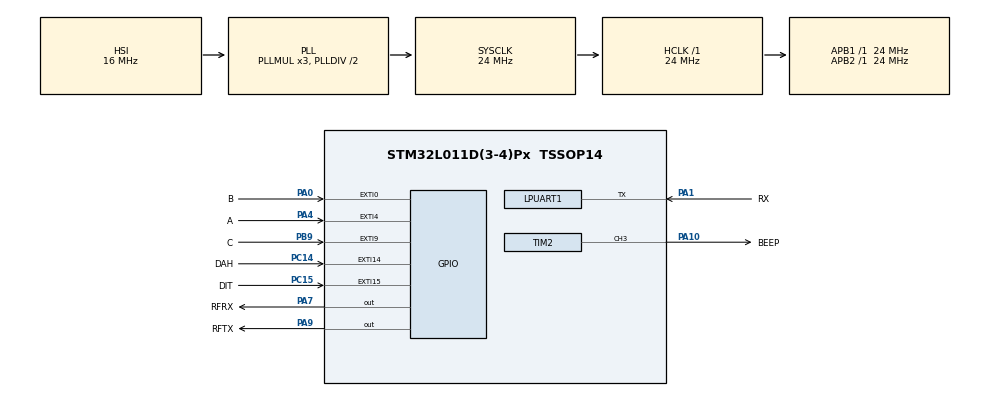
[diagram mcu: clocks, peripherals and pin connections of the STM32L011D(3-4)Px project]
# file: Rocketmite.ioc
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Dma.LPUART1_RX.0.Direction=DMA_PERIPH_TO_MEMORY
Dma.LPUART1_RX.0.Instance=DMA1_Channel3
Dma.LPUART1_RX.0.MemDataAlignment=DMA_MDATAALIGN_BYTE
Dma.LPUART1_RX.0.MemInc=DMA_MINC_ENABLE
Dma.LPUART1_RX.0.Mode=DMA_NORMAL
Dma.LPUART1_RX.0.PeriphDataAlignment=DMA_PDATAALIGN_BYTE
Dma.LPUART1_RX.0.PeriphInc=DMA_PINC_DISABLE
Dma.LPUART1_RX.0.Priority=DMA_PRIORITY_LOW
Dma.Request0=LPUART1_RX
LPUART1.BaudRate=115200
LPUART1.Mode=UART_MODE_RX
Mcu.Family=STM32L0
Mcu.Name=STM32L011D(3-4)Px
Mcu.Package=TSSOP14
NVIC.DMA1_Channel2_3_IRQn=true\:0\:0\:false\:false\:true\:false\:true\:true
NVIC.LPUART1_IRQn=true\:0\:0\:false\:false\:true\:true\:true\:true
NVIC.TIM21_IRQn=true\:2\:0\:true\:false\:true\:true\:true\:true
PA0-CK_IN.GPIO_Label=B
PA0-CK_IN.GPIO_ModeDefaultEXTI=GPIO_MODE_EVT_FALLING
PA0-CK_IN.Signal=GPXTI0
PA1.GPIO_Label=RX
PA1.Mode=Half_duplex(single_wire_mode)
PA1.Signal=LPUART1_TX
PA10.GPIO_Label=BEEP
PA10.Signal=S_TIM2_CH3
PA13.Mode=Serial_Wire
PA13.Signal=SYS_SWDIO
PA14.Mode=Serial_Wire
PA14.Signal=SYS_SWCLK
PA4.GPIO_Label=A
PA4.GPIO_ModeDefaultEXTI=GPIO_MODE_IT_FALLING
PA4.Signal=GPXTI4
PA7.GPIO_Label=RFRX
PA7.Signal=GPIO_Output
PA9.GPIO_Label=RFTX
PA9.Signal=GPIO_Output
PB9-BOOT0.GPIO_Label=C
PB9-BOOT0.Signal=GPXTI9
PC14-OSC32_IN.GPIO_Label=DAH
PC14-OSC32_IN.GPIO_ModeDefaultEXTI=GPIO_MODE_IT_FALLING
PC14-OSC32_IN.GPIO_PuPd=GPIO_PULLUP
PC14-OSC32_IN.Signal=GPXTI14
PC15-OSC32_OUT.GPIO_Label=DIT
PC15-OSC32_OUT.GPIO_ModeDefaultEXTI=GPIO_MODE_IT_FALLING
PC15-OSC32_OUT.GPIO_PuPd=GPIO_PULLUP
PC15-OSC32_OUT.Signal=GPXTI15
ProjectManager.HeapSize=0x200
ProjectManager.StackSize=0x400
ProjectManager.TargetToolchain=MDK-ARM V5.32
RCC.AHBFreq_Value=24000000
RCC.APB1Freq_Value=24000000
RCC.APB1TimFreq_Value=24000000
RCC.APB2Freq_Value=24000000
RCC.APB2TimFreq_Value=24000000
RCC.HCLKFreq_Value=24000000
RCC.HSE_VALUE=8000000
RCC.HSI16_VALUE=16000000
RCC.HSI_VALUE=16000000
RCC.LSE_VALUE=32768
RCC.MSI_VALUE=2097000
RCC.SYSCLKFreq_VALUE=24000000
RCC.SYSCLKSource=RCC_SYSCLKSOURCE_PLLCLK
RCC.VCOOutputFreq_Value=48000000
SH.S_TIM2_CH3.0=TIM2_CH3,PWM Generation3 CH3
TIM2.AutoReloadPreload=TIM_AUTORELOAD_PRELOAD_ENABLE
TIM2.Channel-PWM\ Generation3\ CH3=TIM_CHANNEL_3
TIM2.OCMode_PWM-PWM\ Generation3\ CH3=TIM_OCMODE_PWM2
TIM2.OCPolarity_3=TIM_OCPOLARITY_LOW
TIM2.Period=1000-1
TIM2.Prescaler=24-1
TIM2.Pulse-PWM\ Generation3\ CH3=1000
TIM21.AutoReloadPreload=TIM_AUTORELOAD_PRELOAD_ENABLE
TIM21.Period=2000-1
TIM21.Prescaler=23-1
VP_TIM21_VS_ClockSourceINT.Mode=Internal
VP_TIM2_VS_ClockSourceINT.Mode=Internal
board=custom

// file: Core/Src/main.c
/* USER CODE BEGIN Header */
/**
  ******************************************************************************
  * @file           : main.c
  * @brief          : Main program body
  ******************************************************************************
  * @attention
  *
  * Copyright (c) 2024 STMicroelectronics.
  * All rights reserved.
  *
  * This software is licensed under terms that can be found in the LICENSE file
  * in the root directory of this software component.
  * If no LICENSE file comes with this software, it is provided AS-IS.
  *
  ******************************************************************************
  */
/* USER CODE END Header */
#include "main.h"
#include "dma.h"
#include "usart.h"
#include "tim.h"
#include "gpio.h"

void SystemClock_Config(void);

int main(void)
{

  /* MCU Configuration--------------------------------------------------------*/

  /* Reset of all peripherals, Initializes the Flash interface and the Systick. */
  HAL_Init();

  /* Configure the system clock */
  SystemClock_Config();

  /* Initialize all configured peripherals */
  MX_GPIO_Init();
  MX_DMA_Init();
  MX_TIM2_Init();
  MX_LPUART1_UART_Init();
  MX_TIM21_Init();
  /* USER CODE BEGIN 2 */
	HAL_TIM_Base_Start_IT(&htim21);//使能定时器中断，轮询检查按键
  HAL_TIM_PWM_Start(&htim2,TIM_CHANNEL_3);//使能PWM通道输出
  /* USER CODE END 2 */

  /* Infinite loop */
  while (1)
  {

  }
}

void SystemClock_Config(void)
{
  RCC_OscInitTypeDef RCC_OscInitStruct = {0};
  RCC_ClkInitTypeDef RCC_ClkInitStruct = {0};
  RCC_PeriphCLKInitTypeDef PeriphClkInit = {0};

  /** Configure the main internal regulator output voltage
  */
  __HAL_PWR_VOLTAGESCALING_CONFIG(PWR_REGULATOR_VOLTAGE_SCALE1);

  /** Initializes the RCC Oscillators according to the specified parameters
  * in the RCC_OscInitTypeDef structure.
  */
  RCC_OscInitStruct.OscillatorType = RCC_OSCILLATORTYPE_HSI;
  RCC_OscInitStruct.HSIState = RCC_HSI_ON;
  RCC_OscInitStruct.HSICalibrationValue = RCC_HSICALIBRATION_DEFAULT;
  RCC_OscInitStruct.PLL.PLLState = RCC_PLL_ON;
  RCC_OscInitStruct.PLL.PLLSource = RCC_PLLSOURCE_HSI;
  RCC_OscInitStruct.PLL.PLLMUL = RCC_PLLMUL_3;
  RCC_OscInitStruct.PLL.PLLDIV = RCC_PLLDIV_2;
  if (HAL_RCC_OscConfig(&RCC_OscInitStruct) != HAL_OK)
  {
    Error_Handler();
  }

  /** Initializes the CPU, AHB and APB buses clocks
  */
  RCC_ClkInitStruct.ClockType = RCC_CLOCKTYPE_HCLK|RCC_CLOCKTYPE_SYSCLK
                              |RCC_CLOCKTYPE_PCLK1|RCC_CLOCKTYPE_PCLK2;
  RCC_ClkInitStruct.SYSCLKSource = RCC_SYSCLKSOURCE_PLLCLK;
  RCC_ClkInitStruct.AHBCLKDivider = RCC_SYSCLK_DIV1;
  RCC_ClkInitStruct.APB1CLKDivider = RCC_HCLK_DIV1;
  RCC_ClkInitStruct.APB2CLKDivider = RCC_HCLK_DIV1;

  if (HAL_RCC_ClockConfig(&RCC_ClkInitStruct, FLASH_LATENCY_1) != HAL_OK)
  {
    Error_Handler();
  }
  PeriphClkInit.PeriphClockSelection = RCC_PERIPHCLK_LPUART1;
  PeriphClkInit.Lpuart1ClockSelection = RCC_LPUART1CLKSOURCE_PCLK1;
  if (HAL_RCCEx_PeriphCLKConfig(&PeriphClkInit) != HAL_OK)
  {
    Error_Handler();
  }
}

void Error_Handler(void)
{
  __disable_irq();
  while (1)
  {
  }
}
